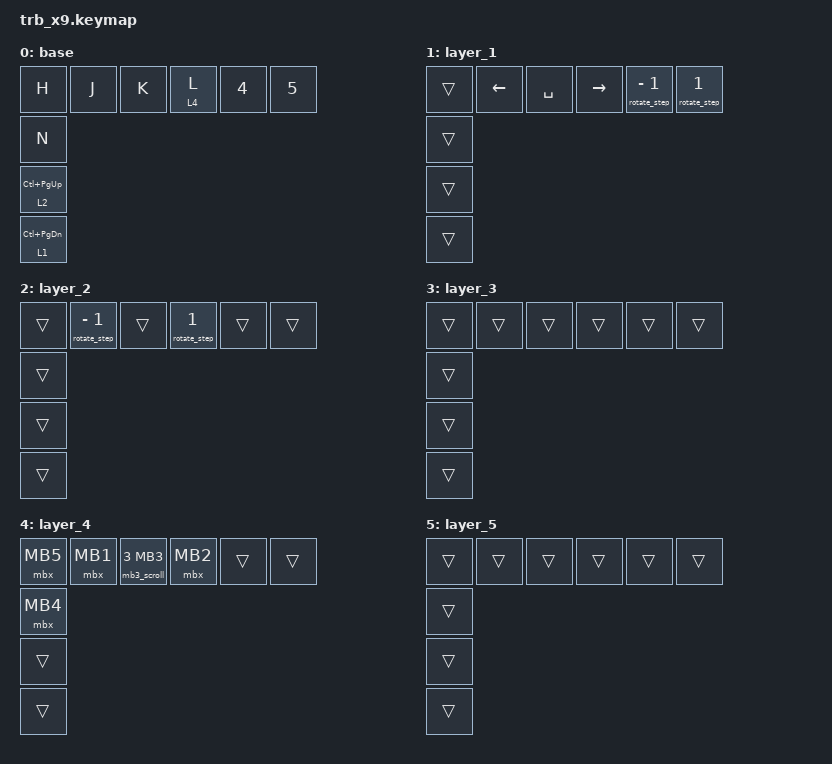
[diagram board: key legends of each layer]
#include <behaviors.dtsi>
#include <dt-bindings/zmk/keys.h>
#include <dt-bindings/zmk/pointing.h>

/ {
    // --- Auto mouse layer exit -------------------------------------------
    // &mlx turns layer 4 off delay-ms after the last mouse button is
    // released; pressing a mouse button again within that time cancels it
    // (so double clicks and drags keep working). Change delay-ms to adjust.
    mlx: mouse_layer_exit {
        compatible = "zmk,behavior-mouse-layer-exit";
        #binding-cells = <0>;
        layer = <4>;
        delay-ms = <300>;
    };

    macros {
        // Mouse button that also ends the mouse layer: &mbx MB1
        mbx: mbx {
            compatible = "zmk,behavior-macro-one-param";
            #binding-cells = <1>;
            wait-ms = <0>;
            tap-ms = <0>;
            bindings
                = <&macro_press &mlx>
                , <&macro_param_1to1 &macro_press &mkp MACRO_PLACEHOLDER>
                , <&macro_pause_for_release>
                , <&macro_param_1to1 &macro_release &mkp MACRO_PLACEHOLDER>
                , <&macro_release &mlx>
                ;
        };

        // Momentary layer that also ends the mouse layer (hold side of
        // &mb3_scroll): &mo_x 3
        mo_x: mo_x {
            compatible = "zmk,behavior-macro-one-param";
            #binding-cells = <1>;
            wait-ms = <0>;
            tap-ms = <0>;
            bindings
                = <&macro_press &mlx>
                , <&macro_param_1to1 &macro_press &mo MACRO_PLACEHOLDER>
                , <&macro_pause_for_release>
                , <&macro_param_1to1 &macro_release &mo MACRO_PLACEHOLDER>
                , <&macro_release &mlx>
                ;
        };
    };

    combos {
        compatible = "zmk,combos";

        boot {
            bindings = <&bootloader>;
            key-positions = <0 1 2 3>;
        };

        // Mouse layer only: &mb3_scroll (pos 2) + &mbx MB2 (pos 3) together
        // = plain MB3 press
        mb3_combo {
            bindings = <&mkp MB3>;
            key-positions = <2 3>;
            layers = <4>;
            timeout-ms = <50>;
        };
    };

    keymap {
        compatible = "zmk,keymap";

        base {
            bindings = <
&kp H                &kp J  &kp K  &lt 4 L  &kp N4  &kp N5
&kp N
&lt 2 LC(PG_UP)
&lt 1 LC(PAGE_DOWN)
            >;
        };

        layer_1 {
            bindings = <
&trans  &kp LEFT  &kp SPACE  &kp RIGHT  &rotate_step (-1)  &rotate_step 1
&trans
&trans
&trans
            >;
        };

        layer_2 {
            bindings = <
&trans  &rotate_step (-1)  &trans  &rotate_step 1  &trans  &trans
&trans
&trans
&trans
            >;
        };

        layer_3 {
            bindings = <
&trans  &trans  &trans  &trans  &trans  &trans
&trans
&trans
&trans
            >;
        };

        // Auto mouse layer: turned on by moving the trackball, stays on until
        // a mouse button is used (then off after &mlx delay-ms) or another
        // key is pressed. See mouse_temp_layer in trb_x9.overlay.

        layer_4 {
            bindings = <
&mbx MB5  &mbx MB1  &mb3_scroll 3 MB3  &mbx MB2  &trans  &trans
&mbx MB4
&trans
&trans
            >;
        };

        layer_5 {
            bindings = <
&trans  &trans  &trans  &trans  &trans  &trans
&trans
&trans
&trans
            >;
        };
    };
};
